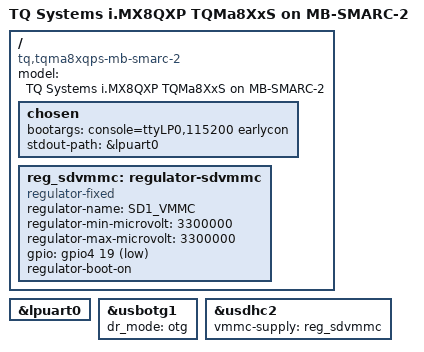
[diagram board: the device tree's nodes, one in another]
// SPDX-License-Identifier: GPL-2.0+
/*
 * Copyright 2018 - 2020 TQ Systems GmbH
 */

/dts-v1/;

#include "fsl-imx8qxp-tqma8xqps.dtsi"

/ {
	model = "TQ Systems i.MX8QXP TQMa8XxS on MB-SMARC-2";
	compatible = "tq,tqma8xqps-mb-smarc-2", "tq,tqma8xqps", "fsl,imx8qxp";

	chosen {
		bootargs = "console=ttyLP0,115200 earlycon";
		stdout-path = &lpuart0;
	};

	reg_sdvmmc: regulator-sdvmmc {
		compatible = "regulator-fixed";
		regulator-name = "SD1_VMMC";
		regulator-min-microvolt = <3300000>;
		regulator-max-microvolt = <3300000>;
		gpio = <&gpio4 19 GPIO_ACTIVE_LOW>;
		regulator-boot-on;
	};
};

&lpuart0 {
	status = "okay";
};

&usbotg1 {
	dr_mode = "otg";
	status = "okay";
};

&usdhc2 {
	vmmc-supply = <&reg_sdvmmc>;
	status = "okay";
};
